# PIC32CM2532JH00064 register map
Vendor: Microchip Technology; Series: PIC32CMJH00; File version: 0
CPU: CM0+ r0p0, little endian, MPU, no FPU, VTOR, 2 interrupt priority bits, 32 interrupts
Registers are 32-bit, read-write, reset 0x0 unless marked. A register's access mark holds for its fields unless they carry their own. Offsets are from the block's base; [hi:lo] are bit positions; {n}, {i} and the like mark numbered series; 'fields as' and 'values as' point back to an identical list.

## MPU — Memory Protection Unit
Base 0xE000ED90
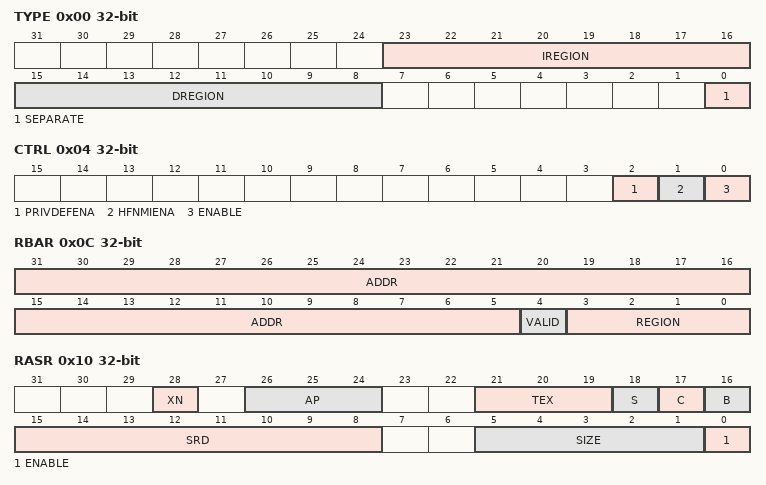
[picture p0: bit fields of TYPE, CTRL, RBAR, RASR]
0x00 TYPE ro — MPU Type Register
  [23:16] IREGION — Number of Instruction Regions
  [15:8] DREGION — Number of Data Regions
  [0] SEPARATE — Separate instruction and Data Memory MapsRegions
0x04 CTRL — MPU Control Register
  [2] PRIVDEFENA — Enables privileged software access to default memory map
  [1] HFNMIENA — Enable Hard Fault and NMI handlers
  [0] ENABLE — MPU Enable
0x08 RNR — MPU Region Number Register
  [7:0] REGION — Region referenced by RBAR and RASR
0x0C RBAR — MPU Region Base Address Register
  [31:5] ADDR — Region base address
  [4] VALID — Region number valid
  [3:0] REGION — Region number
0x10 RASR — MPU Region Attribute and Size Register
  [28] XN — Execute Never Attribute
  [26:24] AP — Access Permission
  [21:19] TEX — TEX bit
  [18] S — Shareable bit
  [17] C — Cacheable bit
  [16] B — Bufferable bit
  [15:8] SRD — Sub-region disable
  [5:1] SIZE — Region Size
  [0] ENABLE — Region Enable

## MTB — Cortex-M0+ Micro-Trace Buffer
Base 0x41008000
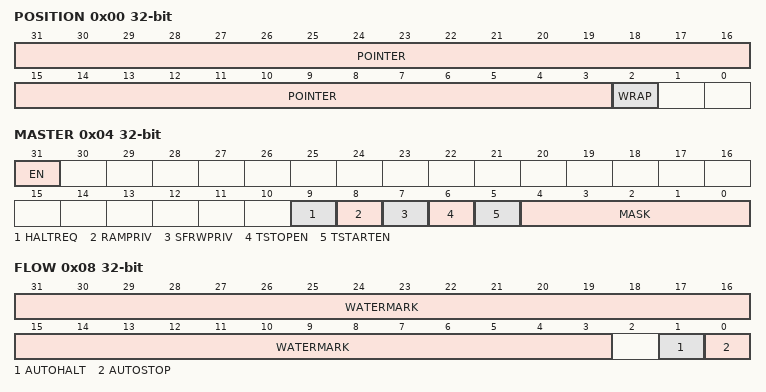
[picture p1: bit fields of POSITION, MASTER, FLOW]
0x00 POSITION — MTB Position
  [31:3] POINTER — Trace Packet Location Pointer
  [2] WRAP — Pointer Value Wraps
0x04 MASTER — MTB Master
  [31] EN — Main Trace Enable
  [9] HALTREQ — Halt Request
  [8] RAMPRIV — SRAM Privilege
  [7] SFRWPRIV — Special Function Register Write Privilege
  [6] TSTOPEN — Trace Stop Input Enable
  [5] TSTARTEN — Trace Start Input Enable
  [4:0] MASK — Maximum Value of the Trace Buffer in SRAM
0x08 FLOW — MTB Flow
  [31:3] WATERMARK — Watermark value
  [1] AUTOHALT — Auto Halt Request
  [0] AUTOSTOP — Auto Stop Tracing
0x0C BASE ro — MTB Base
0xF00 ITCTRL — MTB Integration Mode Control
0xFA0 CLAIMSET write-1-sets — MTB Claim Set
0xFA4 CLAIMCLR write-1-clears — MTB Claim Clear
0xFB0 LOCKACCESS — MTB Lock Access
0xFB4 LOCKSTATUS ro — MTB Lock Status
0xFB8 AUTHSTATUS ro — MTB Authentication Status
0xFBC DEVARCH ro — MTB Device Architecture
0xFC8 DEVID ro — MTB Device Configuration
0xFCC DEVTYPE ro — MTB Device Type
{0xFC0+4i} PID{i} ro (i=4..7) — Peripheral Identification {i}
{0xFE0+4i} PID{i} ro (i=0..3) — Peripheral Identification {i}
{0xFF0+4i} CID{i} ro (i=0..3) — Component Identification {i}

## NVIC — Nested Vectored Interrupt Controller
Base 0xE000E100
0x00 ISER — Interrupt Set Enable Register
  [31:0] SETENA — Interrupt set enable bits
0x80 ICER — Interrupt Clear Enable Register
  [31:0] CLRENA — Interrupt clear-enable bits
0x100 ISPR — Interrupt Set Pending Register
  [31:0] SETPEND — Interrupt set-pending bits
0x180 ICPR — Interrupt Clear Pending Register
  [31:0] CLRPEND — Interrupt clear-pending bits
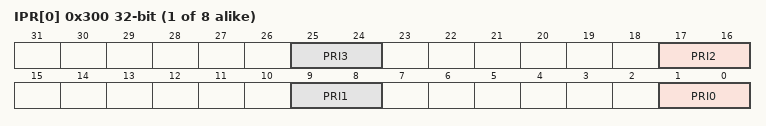
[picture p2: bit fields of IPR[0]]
{0x300+4i} IPR[{i}] (i=0..7) — Interrupt Priority Register n
  [8n+1:8n] PRI{n} (n=0..3) — Priority of interrupt n

## OSC32KCTRL — 32k Oscillators Control
Base 0x40001400
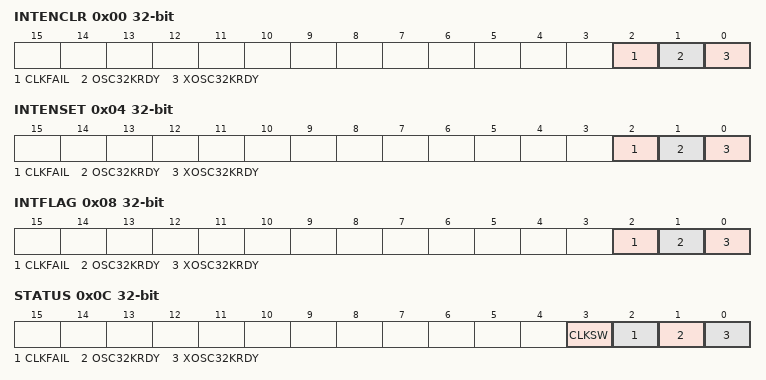
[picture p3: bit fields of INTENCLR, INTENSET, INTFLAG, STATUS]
0x00 INTENCLR write-1-clears — Interrupt Enable Clear
  [2] CLKFAIL — XOSC32K Clock Failure Detector Interrupt Enable
  [1] OSC32KRDY — OSC32K Ready Interrupt Enable
  [0] XOSC32KRDY — XOSC32K Ready Interrupt Enable
0x04 INTENSET write-1-sets — Interrupt Enable Set
  fields as INTENCLR
0x08 INTFLAG write-1-clears — Interrupt Flag Status and Clear
  [2] CLKFAIL — XOSC32K Clock Failure Detector
  [1] OSC32KRDY — OSC32K Ready
  [0] XOSC32KRDY — XOSC32K Ready
0x0C STATUS ro — Power and Clocks Status
  [3] CLKSW — XOSC32K Clock switch
  [2] CLKFAIL — XOSC32K Clock Failure Detector
  [1] OSC32KRDY — OSC32K Ready
  [0] XOSC32KRDY — XOSC32K Ready
0x10 RTCCTRL — RTC Clock Selection
  [2:0] RTCSEL
    0=ULP1K (1.024kHz from 32kHz internal ULP oscillator); 1=ULP32K (32.768kHz from 32kHz internal ULP oscillator); 2=OSC1K (1.024kHz from 32.768kHz internal oscillator); 3=OSC32K (32.768kHz from 32.768kHz internal oscillator); 4=XOSC1K (1.024kHz from 32.768kHz external crystal oscillator); 5=XOSC32K (32.768kHz from 32.768kHz external crystal oscillator)
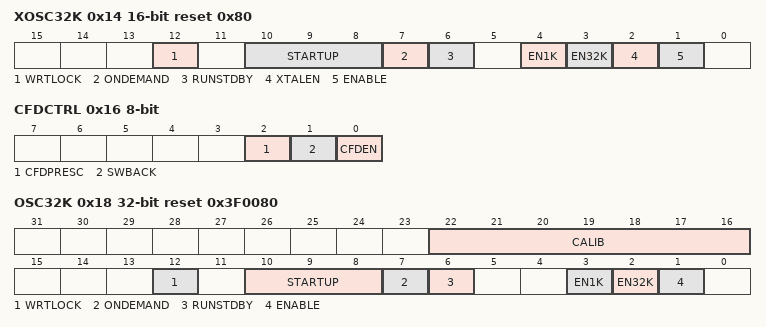
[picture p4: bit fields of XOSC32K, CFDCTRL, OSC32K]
0x14 XOSC32K 16-bit reset 0x80 — 32kHz External Crystal Oscillator (XOSC32K) Control
  [12] WRTLOCK — Write Lock
  [10:8] STARTUP — Oscillator Start-Up Time
    0=CYCLE1 (122 us); 1=CYCLE32 (1.06 ms); 2=CYCLE2048 (62.6 ms); 3=CYCLE4096 (125 ms); 4=CYCLE16384 (500 ms); 5=CYCLE32768 (1 s); 6=CYCLE65536 (2 s); 7=CYCLE131072 (4 s)
  [7] ONDEMAND — On Demand Control
  [6] RUNSTDBY — Run in Standby
  [4] EN1K — 1kHz Output Enable
  [3] EN32K — 32kHz Output Enable
  [2] XTALEN — Crystal Oscillator Enable
  [1] ENABLE — Oscillator Enable
0x16 CFDCTRL 8-bit — Clock Failure Detector Control
  [2] CFDPRESC — Clock Failure Detector Prescaler
  [1] SWBACK — Clock Switch Back Enable
  [0] CFDEN — Clock Failure Detector Enable
0x17 EVCTRL 8-bit — Event Control
  [0] CFDEO — Clock Failure Detector Event Output Enable
0x18 OSC32K reset 0x3F0080 — 32kHz Internal Oscillator (OSC32K) Control
  [22:16] CALIB — Oscillator Calibration
  [12] WRTLOCK — Write Lock
  [10:8] STARTUP — Oscillator Start-Up Time
    0=CYCLE3 (0.183 ms); 1=CYCLE4 (0.214 ms); 2=CYCLE6 (0.275 ms); 3=CYCLE10 (0.397 ms); 4=CYCLE18 (0.641 ms); 5=CYCLE34 (1.129 ms); 6=CYCLE66 (2.106 ms); 7=CYCLE130 (4.059 ms)
  [7] ONDEMAND — On Demand Control
  [6] RUNSTDBY — Run in Standby
  [3] EN1K — 1kHz Output Enable
  [2] EN32K — 32kHz Output Enable
  [1] ENABLE — Oscillator Enable
0x1C OSCULP32K — 32kHz Ultra Low Power Internal Oscillator (OSCULP32K) Control
  [15] WRTLOCK — Write Lock

## Notices in the file
Copyright (c) 2026 Microchip Technology Inc.
SPDX-License-Identifier: Apache-2.0
Licensed under the Apache License, Version 2.0 (the "License");
you may not use this file except in compliance with the License.
You may obtain a copy of the License at
http://www.apache.org/licenses/LICENSE-2.0
Unless required by applicable law or agreed to in writing, software
distributed under the License is distributed on an "AS IS" BASIS,
WITHOUT WARRANTIES OR CONDITIONS OF ANY KIND, either express or implied.
See the License for the specific language governing permissions and
limitations under the License.
